VERSION ""

NS_ :

BS_: 500

BU_: Vector__XXX

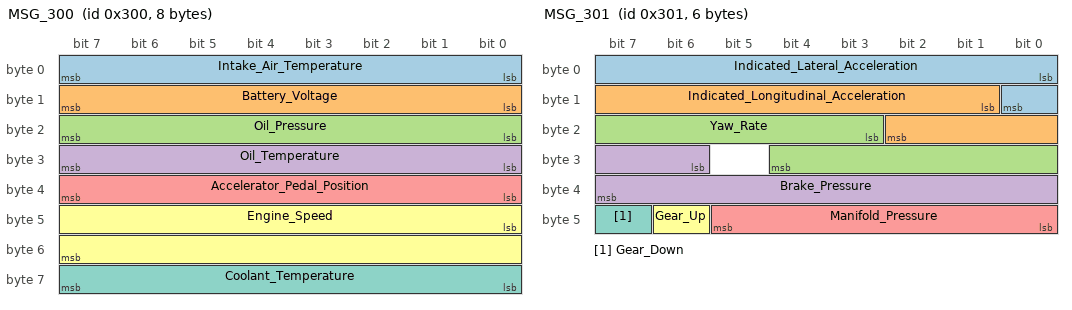
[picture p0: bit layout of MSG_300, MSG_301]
BO_ 768 MSG_300: 8 Vector__XXX
 SG_ Intake_Air_Temperature : 0|8@1+ (0.75,-48) [0|0] "��C" Vector__XXX
 SG_ Battery_Voltage : 8|8@1+ (0.05,5) [0|0] "V" Vector__XXX
 SG_ Oil_Pressure : 16|8@1+ (0.04,0) [0|10] "bar" Vector__XXX
 SG_ Oil_Temperature : 24|8@1+ (1,-60) [-60|192] "��C" Vector__XXX
 SG_ Accelerator_Pedal_Position : 32|8@1+ (0.4,0) [0|101.6] "%" Vector__XXX
 SG_ Engine_Speed : 40|16@1+ (0.25,0) [0|16383] "rpm" Vector__XXX
 SG_ Coolant_Temperature : 56|8@1+ (0.75,-48) [-48|142.5] "��C" Vector__XXX

BO_ 769 MSG_301: 6 Vector__XXX
 SG_ Indicated_Lateral_Acceleration : 0|9@1+ (0.01,-2.55) [-2.55|2.55] "g" Vector__XXX
 SG_ Indicated_Longitudinal_Acceleration : 9|10@1+ (0.03125,-16) [-16|15.90625] "m/s��" Vector__XXX
 SG_ Yaw_Rate : 19|10@1+ (0.1,0) [0|102.2] "��/s" Vector__XXX
 SG_ Brake_Pressure : 30|10@1+ (0.3,-30) [-30|276] "bar" Vector__XXX
 SG_ Manifold_Pressure : 40|6@1+ (18,0) [0|1116] "mbar" Vector__XXX
 SG_ Gear_Up : 46|1@1+ (1,0) [0|1] "" Vector__XXX
 SG_ Gear_Down : 47|1@1+ (1,0) [0|1] "" Vector__XXX

BO_ 770 MSG_302: 8 Vector__XXX
 SG_ Indicated_Vehicle_Speed_kph : 0|16@1+ (0.01,0) [0|655.32] "km/h" Vector__XXX
 SG_ Indicated_Vehicle_Speed_mph : 0|16@1+ (0.00621,0) [0|406.95372] "mph" Vector__XXX
 SG_ Wheel_Speed_FL_kph : 16|12@1+ (0.1,0) [0|409.2] "km/h" Vector__XXX
 SG_ Wheel_Speed_FL_mph : 16|12@1+ (0.0621,0) [0|254.1132] "mph" Vector__XXX
 SG_ Wheel_Speed_FR_kph : 28|12@1+ (0.1,0) [0|409.2] "km/h" Vector__XXX
 SG_ Wheel_Speed_FR_mph : 28|12@1+ (0.0621,0) [0|254.1132] "mph" Vector__XXX
 SG_ Wheel_Speed_RL_kph : 40|12@1+ (0.1,0) [0|409.2] "km/h" Vector__XXX
 SG_ Wheel_Speed_RL_mph : 40|12@1+ (0.0621,0) [0|254.1132] "mph" Vector__XXX
 SG_ Wheel_Speed_RR_kph : 52|12@1+ (0.1,0) [0|409.2] "km/h" Vector__XXX
 SG_ Wheel_Speed_RR_mph : 52|12@1+ (0.0621,0) [0|254.1132] "mph" Vector__XXX

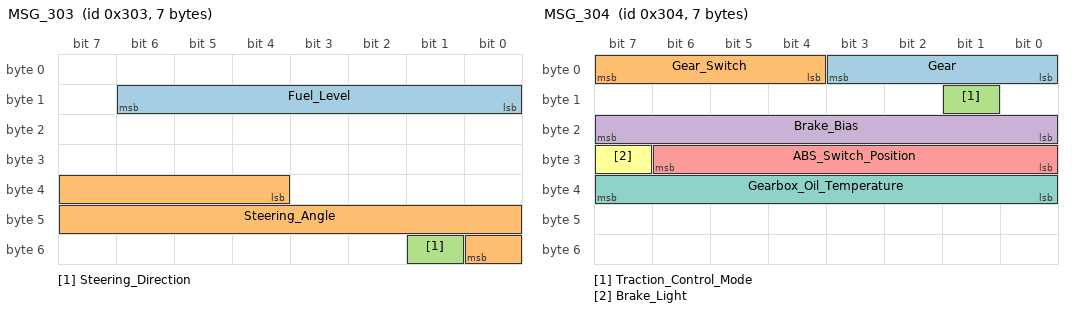
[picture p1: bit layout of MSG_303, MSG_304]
BO_ 771 MSG_303: 7 Vector__XXX
 SG_ Fuel_Level : 8|7@1+ (1,0) [0|0] "L" Vector__XXX
 SG_ Steering_Angle : 36|13@1+ (0.1,0) [0|800] "" Vector__XXX
 SG_ Steering_Direction : 49|1@1+ (1,0) [0|1] "" Vector__XXX

BO_ 772 MSG_304: 7 Vector__XXX
 SG_ Gear : 0|4@1+ (1,0) [0|15] "" Vector__XXX
 SG_ Gear_Switch : 4|4@1+ (1,0) [0|15] "" Vector__XXX
 SG_ Traction_Control_Mode : 9|1@1+ (1,0) [0|1] "on/off" Vector__XXX
 SG_ Brake_Bias : 16|8@1- (0.25,0) [0|0] "" Vector__XXX
 SG_ ABS_Switch_Position : 24|7@1+ (1,0) [0|7] "" Vector__XXX
 SG_ Brake_Light : 31|1@1+ (1,0) [0|1] "on/off" Vector__XXX
 SG_ Gearbox_Oil_Temperature : 32|8@1+ (1,-60) [-60|193] "��C" Vector__XXX

BO_ 773 MSG_305: 8 Vector__XXX
 SG_ Throttle_Position : 56|8@1+ (0.392156862745,0) [0|100] "%" Vector__XXX

BO_ 774 MSG_306: 8 Vector__XXX
 SG_ Fuel_Pressure : 32|8@1+ (1,0) [0|255] "bar" Vector__XXX

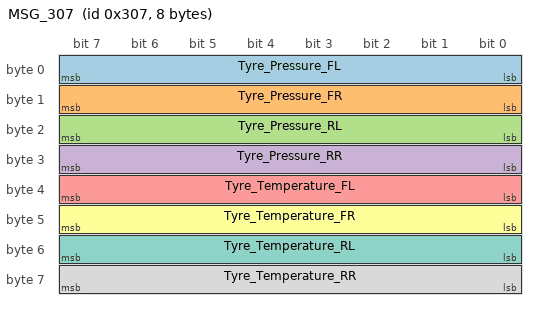
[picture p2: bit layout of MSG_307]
BO_ 775 MSG_307: 8 Vector__XXX
 SG_ Tyre_Pressure_FL : 0|8@1+ (0.1,0) [0|25.5] "bar" Vector__XXX
 SG_ Tyre_Pressure_FR : 8|8@1+ (0.1,0) [0|25.5] "bar" Vector__XXX
 SG_ Tyre_Pressure_RL : 16|8@1+ (0.1,0) [0|25.5] "bar" Vector__XXX
 SG_ Tyre_Pressure_RR : 24|8@1+ (0.1,0) [0|25.5] "bar" Vector__XXX
 SG_ Tyre_Temperature_FL : 32|8@1+ (1,-60) [-60|193] "��C" Vector__XXX
 SG_ Tyre_Temperature_FR : 40|8@1+ (1,-60) [-60|193] "��C" Vector__XXX
 SG_ Tyre_Temperature_RL : 48|8@1+ (1,-60) [-60|193] "��C" Vector__XXX
 SG_ Tyre_Temperature_RR : 56|8@1+ (1,-60) [-60|193] "��C" Vector__XXX
